# STM32F765BGT6 register map
File version: 1.0
Registers are 32-bit, access not given, reset 0x0 unless marked. A register's access mark holds for its fields unless they carry their own. Offsets are from the block's base; [hi:lo] are bit positions; {n}, {i} and the like mark numbered series.

## SPI2
Base 0x40003800
Same registers: SPI3 0x40003C00, SPI1 0x40013000, SPI4 0x40013400, SPI5 0x40015000, SPI6 0x40015400
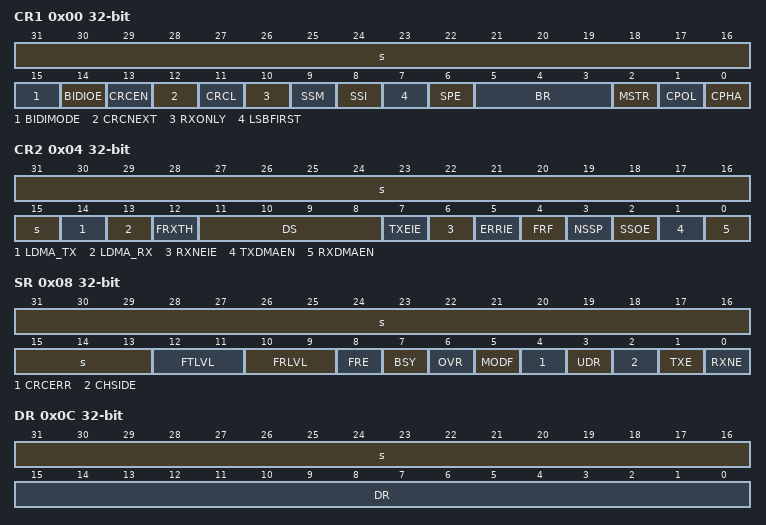
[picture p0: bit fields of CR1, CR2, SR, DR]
0x00 CR1
  [31:16] s, [15] BIDIMODE, [14] BIDIOE, [13] CRCEN, [12] CRCNEXT, [11] CRCL, [10] RXONLY, [9] SSM, [8] SSI, [7] LSBFIRST, [6] SPE, [5:3] BR, [2] MSTR, [1] CPOL, [0] CPHA
0x04 CR2
  [31:15] s, [14] LDMA_TX, [13] LDMA_RX, [12] FRXTH, [11:8] DS, [7] TXEIE, [6] RXNEIE, [5] ERRIE, [4] FRF, [3] NSSP, [2] SSOE, [1] TXDMAEN, [0] RXDMAEN
0x08 SR
  [31:13] s, [12:11] FTLVL, [10:9] FRLVL, [8] FRE, [7] BSY, [6] OVR, [5] MODF, [4] CRCERR, [3] UDR, [2] CHSIDE, [1] TXE, [0] RXNE
0x0C DR
  [31:16] s, [15:0] DR
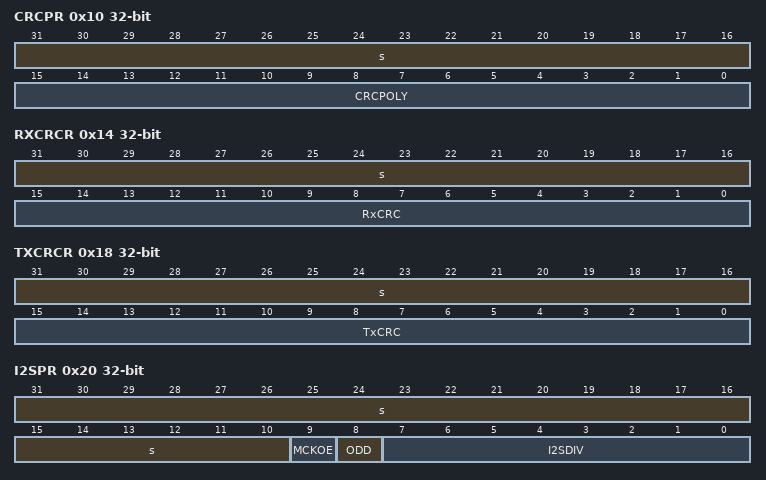
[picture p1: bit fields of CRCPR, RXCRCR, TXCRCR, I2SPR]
0x10 CRCPR
  [31:16] s, [15:0] CRCPOLY
0x14 RXCRCR
  [31:16] s, [15:0] RxCRC
0x18 TXCRCR
  [31:16] s, [15:0] TxCRC
0x1C I2SCFGR
  [12] ASTRTEN, [11] I2SMOD, [10] I2SE, [9:8] I2SCFG, [7] PCMSYNC, [31:6] s, [5:4] I2SSTD, [3] CKPOL, [2:1] DATLEN, [0] CHLEN
0x20 I2SPR
  [31:10] s, [9] MCKOE, [8] ODD, [7:0] I2SDIV

## SPDIFRX
Base 0x40004000
0x00 CR
  [18:16] INSEL, [31:15] s, [14] WFA, [13:12] NBTR, [11] CHSEL, [10] CBDMAEN, [9] PTMSK, [8] CUMSK, [7] VMSK, [6] PMSK, [5:4] DRFMT, [3] RXSTEO, [2] RXDMAEN, [1:0] SPDIFRXEN
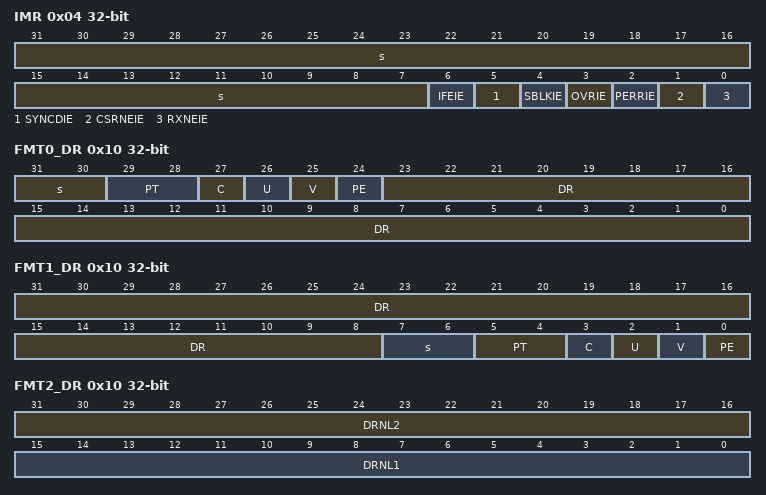
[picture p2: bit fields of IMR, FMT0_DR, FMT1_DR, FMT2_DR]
0x04 IMR
  [31:7] s, [6] IFEIE, [5] SYNCDIE, [4] SBLKIE, [3] OVRIE, [2] PERRIE, [1] CSRNEIE, [0] RXNEIE
0x08 SR
  [30:16] WIDTH5, [31:9] s, [8] TERR, [7] SERR, [6] FERR, [5] SYNCD, [4] SBD, [3] OVR, [2] PERR, [1] CSRNE, [0] RXNE
0x0C IFCR
  [5] SYNCDCF, [4] SBDCF, [3] OVRCF, [2] PERRCF, [31:0] s
0x10 FMT0_DR
  [31:30] s, [29:28] PT, [27] C, [26] U, [25] V, [24] PE, [23:0] DR
0x10 FMT1_DR
  [31:8] DR, [7:6] s, [5:4] PT, [3] C, [2] U, [1] V, [0] PE
0x10 FMT2_DR
  [31:16] DRNL2, [15:0] DRNL1
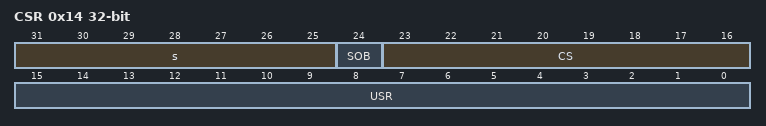
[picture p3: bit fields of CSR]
0x14 CSR
  [31:25] s, [24] SOB, [23:16] CS, [15:0] USR
0x18 DIR
  [28:16] TLO, [31:13] s, [12:0] THI

## USART2
Base 0x40004400
Same registers: USART3 0x40004800, UART4 0x40004C00, UART5 0x40005000, UART7 0x40007800, UART8 0x40007C00, USART1 0x40011000, USART6 0x40011400
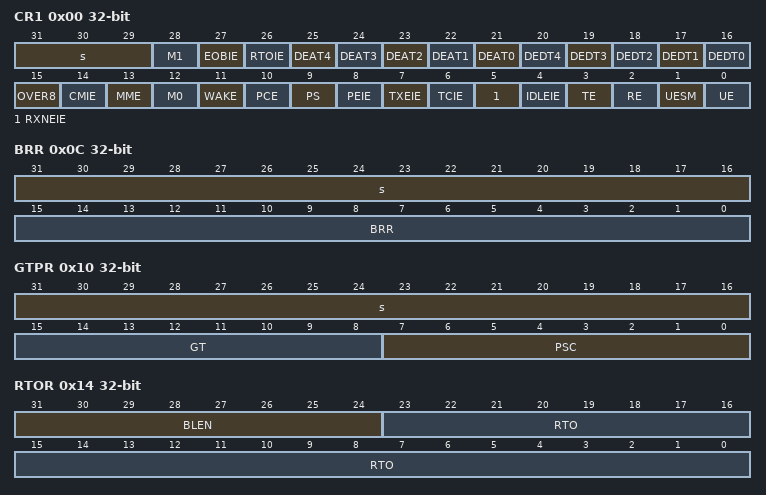
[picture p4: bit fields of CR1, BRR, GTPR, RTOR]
0x00 CR1
  [31:29] s, [28] M1, [27] EOBIE, [26] RTOIE, [n+21] DEAT{n} (n=0..4), [n+16] DEDT{n} (n=0..4), [15] OVER8, [14] CMIE, [13] MME, [12] M0, [11] WAKE, [10] PCE, [9] PS, [8] PEIE, [7] TXEIE, [6] TCIE, [5] RXNEIE, [4] IDLEIE, [3] TE, [2] RE, [1] UESM, [0] UE
0x04 CR2
  [31:24] ADD, [23] RTOEN, [22] ABRMOD1, [21] ABRMOD0, [20] ABREN, [19] MSBFIRST, [18] DATAINV, [17] TXINV, [16] RXINV, [15] SWAP, [14] LINEN, [13:12] STOP, [11] CLKEN, [10] CPOL, [9] CPHA, [8] LBCL, [6] LBDIE, [5] LBDL, [4] ADDM7, [7:0] s
0x08 CR3
  [24] TCBGTIE, [23] UCESM, [22] WUFIE, [21:20] WUS, [19:17] SCARCNT, [31:16] s, [15] DEP, [14] DEM, [13] DDRE, [12] OVRDIS, [11] ONEBIT, [10] CTSIE, [9] CTSE, [8] RTSE, [7] DMAT, [6] DMAR, [5] SCEN, [4] NACK, [3] HDSEL, [2] IRLP, [1] IREN, [0] EIE
0x0C BRR
  [31:16] s, [15:0] BRR
0x10 GTPR
  [31:16] s, [15:8] GT, [7:0] PSC
0x14 RTOR
  [31:24] BLEN, [23:0] RTO
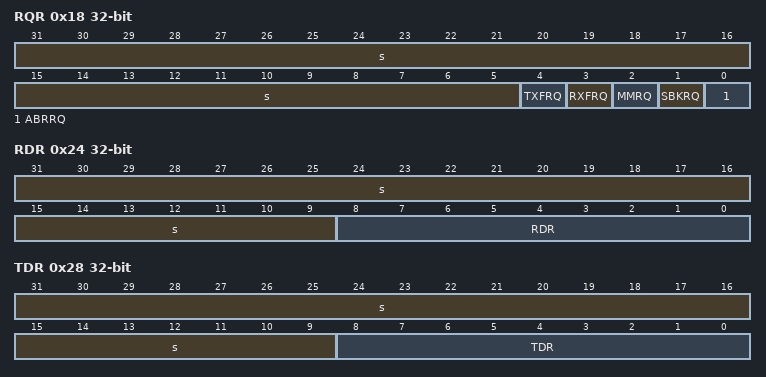
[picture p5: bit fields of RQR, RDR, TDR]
0x18 RQR
  [31:5] s, [4] TXFRQ, [3] RXFRQ, [2] MMRQ, [1] SBKRQ, [0] ABRRQ
0x1C ISR
  [25] TCBGT, [22] REACK, [21] TEACK, [20] WUF, [19] RWU, [18] SBKF, [17] CMF, [16] BUSY, [15] ABRF, [14] ABRE, [31:13] s, [12] EOBF, [11] RTOF, [10] CTS, [9] CTSIF, [8] LBDF, [7] TXE, [6] TC, [5] RXNE, [4] IDLE, [3] ORE, [2] NF, [1] FE, [0] PE
0x20 ICR
  [20] WUCF, [17] CMCF, [12] EOBCF, [11] RTOCF, [9] CTSCF, [8] LBDCF, [7] TCBGTCF, [6] TCCF, [31:5] s, [4] IDLECF, [3] ORECF, [2] NCF, [1] FECF, [0] PECF
0x24 RDR
  [31:9] s, [8:0] RDR
0x28 TDR
  [31:9] s, [8:0] TDR

## I2C1
Base 0x40005400
Same registers: I2C2 0x40005800, I2C3 0x40005C00, I2C4 0x40006000
0x00 CR1
  [23] PECEN, [22] ALERTEN, [21] SMBDEN, [20] SMBHEN, [19] GCEN, [17] NOSTRETCH, [16] SBC, [15] RXDMAEN, [14] TXDMAEN, [31:13] s, [12] ANFOFF, [11:8] DNF, [7] ERRIE, [6] TCIE, [5] STOPIE, [4] NACKIE, [3] ADDRIE, [2] RXIE, [1] TXIE, [0] PE
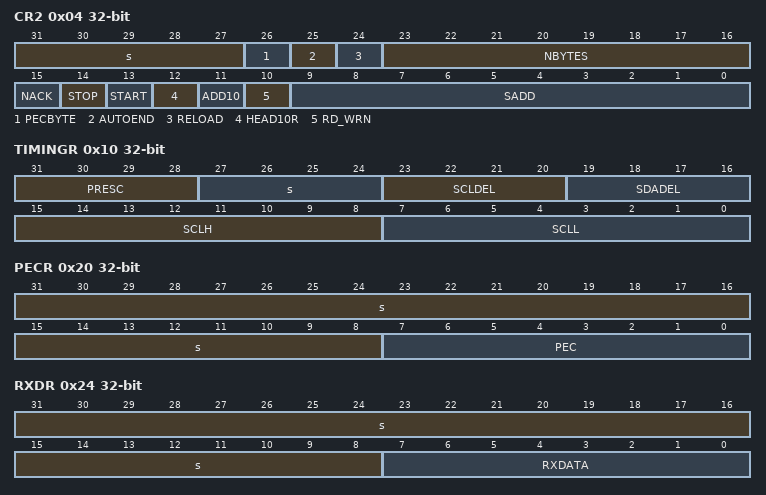
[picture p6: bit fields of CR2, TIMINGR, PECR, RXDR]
0x04 CR2
  [31:27] s, [26] PECBYTE, [25] AUTOEND, [24] RELOAD, [23:16] NBYTES, [15] NACK, [14] STOP, [13] START, [12] HEAD10R, [11] ADD10, [10] RD_WRN, [9:0] SADD
0x08 OAR1
  [15] OA1EN, [31:11] s, [10] OA1MODE, [9:0] OA1
0x0C OAR2
  [15] OA2EN, [10:8] OA2MSK, [7:1] OA2, [31:0] s
0x10 TIMINGR
  [31:28] PRESC, [27:24] s, [23:20] SCLDEL, [19:16] SDADEL, [15:8] SCLH, [7:0] SCLL
0x14 TIMEOUTR
  [31] TEXTEN, [27:16] TIMEOUTB, [15] TIMOUTEN, [30:13] s, [12] TIDLE, [11:0] TIMEOUTA
0x18 ISR
  [23:17] ADDCODE, [16] DIR, [15] BUSY, [31:14] s, [13] ALERT, [12] TIMEOUT, [11] PECERR, [10] OVR, [9] ARLO, [8] BERR, [7] TCR, [6] TC, [5] STOPF, [4] NACKF, [3] ADDR, [2] RXNE, [1] TXIS, [0] TXE
0x1C ICR
  [13] ALERTCF, [12] TIMOUTCF, [11] PECCF, [10] OVRCF, [9] ARLOCF, [8] BERRCF, [5] STOPCF, [4] NACKCF, [3] ADDRCF, [31:0] s
0x20 PECR
  [31:8] s, [7:0] PEC
0x24 RXDR
  [31:8] s, [7:0] RXDATA
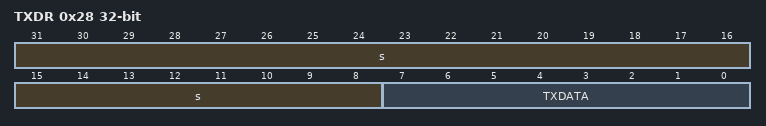
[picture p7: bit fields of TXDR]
0x28 TXDR
  [31:8] s, [7:0] TXDATA
